AUTOSAR XML (schema 3.1.2)
package /Components/SWC_CoEmSTT
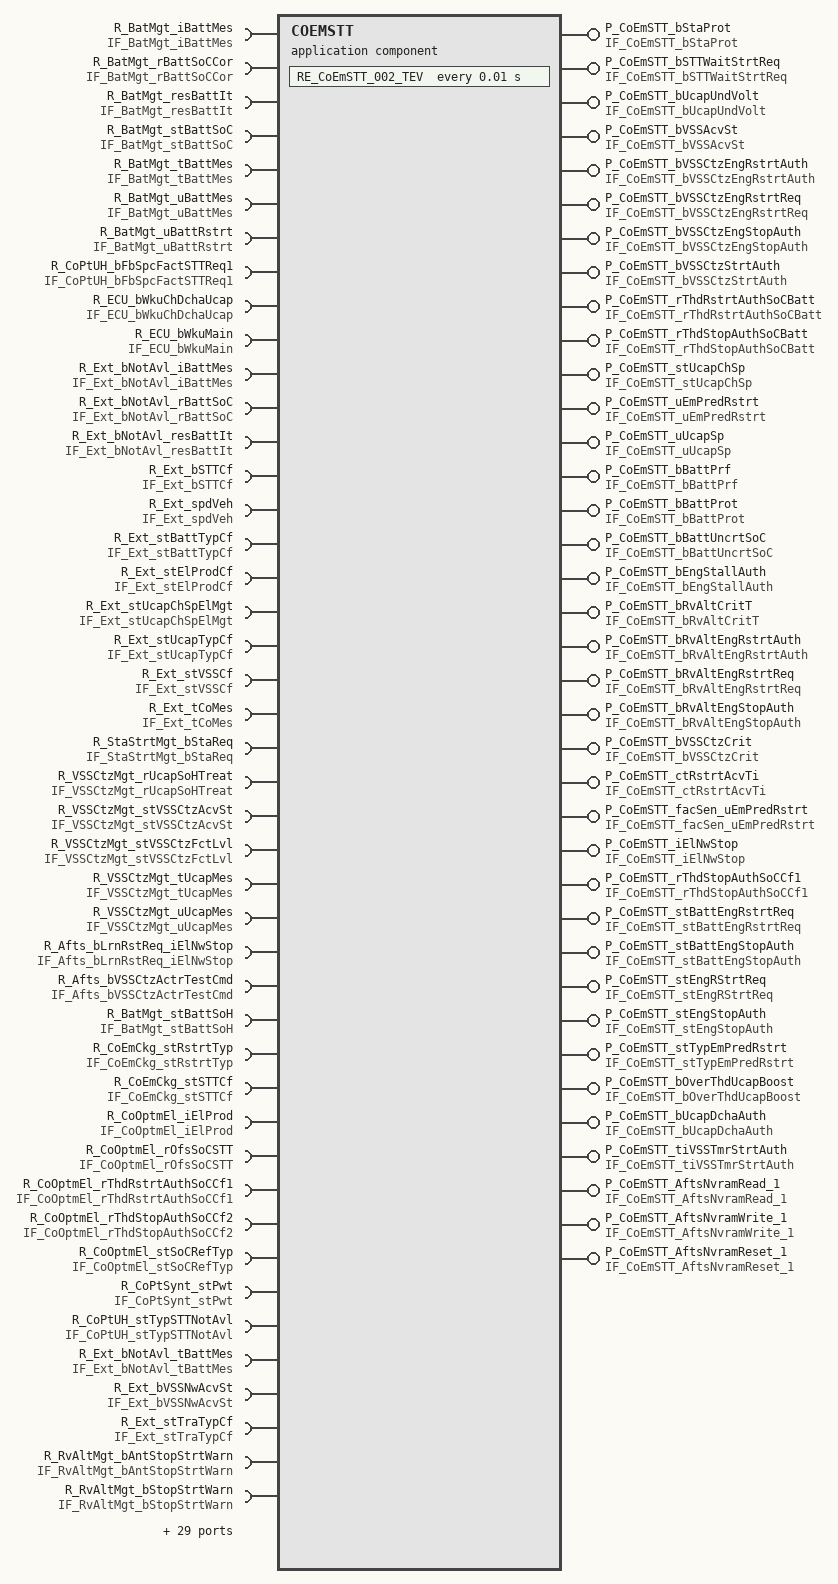
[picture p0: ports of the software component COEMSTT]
  application software component type COEMSTT
    71 x require port:
      R_BatMgt_iBattMes: unqueued-receiver-com-spec{data-element=BatMgt_iBattMes, init-value=BatMgt_iBattMes_in, resync-time=0}, required-interface=IF_BatMgt_iBattMes
      R_BatMgt_rBattSoCCor: unqueued-receiver-com-spec{data-element=BatMgt_rBattSoCCor, init-value=BatMgt_rBattSoCCor_in, resync-time=0}, required-interface=IF_BatMgt_rBattSoCCor
      R_BatMgt_resBattIt: unqueued-receiver-com-spec{data-element=BatMgt_resBattIt, init-value=BatMgt_resBattIt_in, resync-time=0}, required-interface=IF_BatMgt_resBattIt
      R_BatMgt_stBattSoC: unqueued-receiver-com-spec{data-element=BatMgt_stBattSoC, init-value=BatMgt_stBattSoC_in, resync-time=0}, required-interface=IF_BatMgt_stBattSoC
      R_BatMgt_tBattMes: unqueued-receiver-com-spec{data-element=BatMgt_tBattMes, init-value=BatMgt_tBattMes_in, resync-time=0}, required-interface=IF_BatMgt_tBattMes
      R_BatMgt_uBattMes: unqueued-receiver-com-spec{data-element=BatMgt_uBattMes, init-value=BatMgt_uBattMes_in, resync-time=0}, required-interface=IF_BatMgt_uBattMes
      R_BatMgt_uBattRstrt: unqueued-receiver-com-spec{data-element=BatMgt_uBattRstrt, init-value=BatMgt_uBattRstrt_in, resync-time=0}, required-interface=IF_BatMgt_uBattRstrt
      R_CoPtUH_bFbSpcFactSTTReq1: unqueued-receiver-com-spec{data-element=CoPtUH_bFbSpcFactSTTReq1, init-value=ConstantValue, resync-time=0}, required-interface=IF_CoPtUH_bFbSpcFactSTTReq1
      R_ECU_bWkuChDchaUcap: unqueued-receiver-com-spec{data-element=ECU_bWkuChDchaUcap, init-value=ECU_bWkuChDchaUcap_in, resync-time=0}, required-interface=IF_ECU_bWkuChDchaUcap
      R_ECU_bWkuMain: unqueued-receiver-com-spec{data-element=ECU_bWkuMain, init-value=ECU_bWkuMain_in, resync-time=0}, required-interface=IF_ECU_bWkuMain
      R_Ext_bNotAvl_iBattMes: unqueued-receiver-com-spec{data-element=Ext_bNotAvl_iBattMes, init-value=Ext_bNotAvl_iBattMes_in, resync-time=0}, required-interface=IF_Ext_bNotAvl_iBattMes
      R_Ext_bNotAvl_rBattSoC: unqueued-receiver-com-spec{data-element=Ext_bNotAvl_rBattSoC, init-value=Ext_bNotAvl_rBattSoC_in, resync-time=0}, required-interface=IF_Ext_bNotAvl_rBattSoC
      R_Ext_bNotAvl_resBattIt: unqueued-receiver-com-spec{data-element=Ext_bNotAvl_resBattIt, init-value=Ext_bNotAvl_resBattIt_in, resync-time=0}, required-interface=IF_Ext_bNotAvl_resBattIt
      R_Ext_bSTTCf: unqueued-receiver-com-spec{data-element=Ext_bSTTCf, init-value=Ext_bSTTCf_in, resync-time=0}, required-interface=IF_Ext_bSTTCf
      R_Ext_spdVeh: unqueued-receiver-com-spec{data-element=Ext_spdVeh, init-value=Ext_spdVeh_in, resync-time=0}, required-interface=IF_Ext_spdVeh
      R_Ext_stBattTypCf: unqueued-receiver-com-spec{data-element=Ext_stBattTypCf, init-value=Ext_stBattTypCf_in, resync-time=0}, required-interface=IF_Ext_stBattTypCf
      R_Ext_stElProdCf: unqueued-receiver-com-spec{data-element=Ext_stElProdCf, init-value=Ext_stElProdCf_in, resync-time=0}, required-interface=IF_Ext_stElProdCf
      R_Ext_stUcapChSpElMgt: unqueued-receiver-com-spec{data-element=Ext_stUcapChSpElMgt, init-value=Ext_stUcapChSpElMgt_in, resync-time=0}, required-interface=IF_Ext_stUcapChSpElMgt
      R_Ext_stUcapTypCf: unqueued-receiver-com-spec{data-element=Ext_stUcapTypCf, init-value=Ext_stUcapTypCf_in, resync-time=0}, required-interface=IF_Ext_stUcapTypCf
      R_Ext_stVSSCf: unqueued-receiver-com-spec{data-element=Ext_stVSSCf, init-value=Ext_stVSSCf_in, resync-time=0}, required-interface=IF_Ext_stVSSCf
      R_Ext_tCoMes: unqueued-receiver-com-spec{data-element=Ext_tCoMes, init-value=ConstantValue1, resync-time=0}, required-interface=IF_Ext_tCoMes
      R_StaStrtMgt_bStaReq: unqueued-receiver-com-spec{data-element=StaStrtMgt_bStaReq, init-value=StaStrtMgt_bStaReq_in, resync-time=0}, required-interface=IF_StaStrtMgt_bStaReq
      R_VSSCtzMgt_rUcapSoHTreat: unqueued-receiver-com-spec{data-element=VSSCtzMgt_rUcapSoHTreat, init-value=VSSCtzMgt_rUcapSoHTreat_in, resync-time=0}, required-interface=IF_VSSCtzMgt_rUcapSoHTreat
      R_VSSCtzMgt_stVSSCtzAcvSt: unqueued-receiver-com-spec{data-element=VSSCtzMgt_stVSSCtzAcvSt, init-value=VSSCtzMgt_stVSSCtzAcvSt_in, resync-time=0}, required-interface=IF_VSSCtzMgt_stVSSCtzAcvSt
      R_VSSCtzMgt_stVSSCtzFctLvl: unqueued-receiver-com-spec{data-element=VSSCtzMgt_stVSSCtzFctLvl, init-value=VSSCtzMgt_stVSSCtzFctLvl_in, resync-time=0}, required-interface=IF_VSSCtzMgt_stVSSCtzFctLvl
      R_VSSCtzMgt_tUcapMes: unqueued-receiver-com-spec{data-element=VSSCtzMgt_tUcapMes, init-value=VSSCtzMgt_tUcapMes_in, resync-time=0}, required-interface=IF_VSSCtzMgt_tUcapMes
      R_VSSCtzMgt_uUcapMes: unqueued-receiver-com-spec{data-element=VSSCtzMgt_uUcapMes, init-value=VSSCtzMgt_uUcapMes_in, resync-time=0}, required-interface=IF_VSSCtzMgt_uUcapMes
      R_Afts_bLrnRstReq_iElNwStop: unqueued-receiver-com-spec{data-element=Afts_bLrnRstReq_iElNwStop, init-value=Afts_bLrnRstReq_iElNwStop_in, resync-time=0}, required-interface=IF_Afts_bLrnRstReq_iElNwStop
      R_Afts_bVSSCtzActrTestCmd: unqueued-receiver-com-spec{data-element=Afts_bVSSCtzActrTestCmd, init-value=Afts_bVSSCtzActrTestCmd_in, resync-time=0}, required-interface=IF_Afts_bVSSCtzActrTestCmd
      R_BatMgt_stBattSoH: unqueued-receiver-com-spec{data-element=BatMgt_stBattSoH, init-value=BatMgt_stBattSoH_in, resync-time=0}, required-interface=IF_BatMgt_stBattSoH
      R_CoEmCkg_stRstrtTyp: unqueued-receiver-com-spec{data-element=CoEmCkg_stRstrtTyp, init-value=CoEmCkg_stRstrtTyp_in, resync-time=0}, required-interface=IF_CoEmCkg_stRstrtTyp
      R_CoEmCkg_stSTTCf: unqueued-receiver-com-spec{data-element=CoEmCkg_stSTTCf, init-value=CoEmCkg_stSTTCf_in, resync-time=0}, required-interface=IF_CoEmCkg_stSTTCf
      R_CoOptmEl_iElProd: unqueued-receiver-com-spec{data-element=CoOptmEl_iElProd, init-value=CoOptmEl_iElProd_in, resync-time=0}, required-interface=IF_CoOptmEl_iElProd
      R_CoOptmEl_rOfsSoCSTT: unqueued-receiver-com-spec{data-element=CoOptmEl_rOfsSoCSTT, init-value=CoOptmEl_rOfsSoCSTT_in, resync-time=0}, required-interface=IF_CoOptmEl_rOfsSoCSTT
      R_CoOptmEl_rThdRstrtAuthSoCCf1: unqueued-receiver-com-spec{data-element=CoOptmEl_rThdRstrtAuthSoCCf1, init-value=CoOptmEl_rThdRstrtAuthSoCCf1_in, resync-time=0}, required-interface=IF_CoOptmEl_rThdRstrtAuthSoCCf1
      R_CoOptmEl_rThdStopAuthSoCCf2: unqueued-receiver-com-spec{data-element=CoOptmEl_rThdStopAuthSoCCf2, init-value=CoOptmEl_rThdStopAuthSoCCf2_in, resync-time=0}, required-interface=IF_CoOptmEl_rThdStopAuthSoCCf2
      R_CoOptmEl_stSoCRefTyp: unqueued-receiver-com-spec{data-element=CoOptmEl_stSoCRefTyp, init-value=CoOptmEl_stSoCRefTyp_in, resync-time=0}, required-interface=IF_CoOptmEl_stSoCRefTyp
      R_CoPtSynt_stPwt: unqueued-receiver-com-spec{data-element=CoPtSynt_stPwt, init-value=CoPtSynt_stPwt_in, resync-time=0}, required-interface=IF_CoPtSynt_stPwt
      R_CoPtUH_stTypSTTNotAvl: unqueued-receiver-com-spec{data-element=CoPtUH_stTypSTTNotAvl, init-value=CoPtUH_stTypSTTNotAvl_in, resync-time=0}, required-interface=IF_CoPtUH_stTypSTTNotAvl
      R_Ext_bNotAvl_tBattMes: unqueued-receiver-com-spec{data-element=Ext_bNotAvl_tBattMes, init-value=Ext_bNotAvl_tBattMes_in, resync-time=0}, required-interface=IF_Ext_bNotAvl_tBattMes
      R_Ext_bVSSNwAcvSt: unqueued-receiver-com-spec{data-element=Ext_bVSSNwAcvSt, init-value=Ext_bVSSNwAcvSt_in, resync-time=0}, required-interface=IF_Ext_bVSSNwAcvSt
      R_Ext_stTraTypCf: unqueued-receiver-com-spec{data-element=Ext_stTraTypCf, init-value=Ext_stTraTypCf_in, resync-time=0}, required-interface=IF_Ext_stTraTypCf
      R_RvAltMgt_bAntStopStrtWarn: unqueued-receiver-com-spec{data-element=RvAltMgt_bAntStopStrtWarn, init-value=RvAltMgt_bAntStopStrtWarn_in, resync-time=0}, required-interface=IF_RvAltMgt_bAntStopStrtWarn
      R_RvAltMgt_bStopStrtWarn: unqueued-receiver-com-spec{data-element=RvAltMgt_bStopStrtWarn, init-value=RvAltMgt_bStopStrtWarn_in, resync-time=0}, required-interface=IF_RvAltMgt_bStopStrtWarn
      R_RvAltMgt_stRvAltRstrtFbCmd: unqueued-receiver-com-spec{data-element=RvAltMgt_stRvAltRstrtFbCmd, init-value=RvAltMgt_stRvAltRstrtFbCmd_in, resync-time=0}, required-interface=IF_RvAltMgt_stRvAltRstrtFbCmd
      R_RvAltMgt_tRvAltStatEstim: unqueued-receiver-com-spec{data-element=RvAltMgt_tRvAltStatEstim, init-value=RvAltMgt_tRvAltStatEstim_in, resync-time=0}, required-interface=IF_RvAltMgt_tRvAltStatEstim
      R_StaRstrtMgt_bProt10StopInh: unqueued-receiver-com-spec{data-element=StaRstrtMgt_bProt10StopInh, init-value=StaRstrtMgt_bProt10StopInh_in, resync-time=0}, required-interface=IF_StaRstrtMgt_bProt10StopInh
      R_StaRstrtMgt_stStaRstrtFbCmd: unqueued-receiver-com-spec{data-element=StaRstrtMgt_stStaRstrtFbCmd, init-value=StaRstrtMgt_stStaRstrtFbCmd_in, resync-time=0}, required-interface=IF_StaRstrtMgt_stStaRstrtFbCmd
      R_StopStrtEng_stCdnNxtCkg: unqueued-receiver-com-spec{data-element=StopStrtEng_stCdnNxtCkg, init-value=StopStrtEng_stCdnNxtCkg_in, resync-time=0}, required-interface=IF_StopStrtEng_stCdnNxtCkg
      R_VSSCtzMgt_bUcapSerAcvTest: unqueued-receiver-com-spec{data-element=VSSCtzMgt_bUcapSerAcvTest, init-value=VSSCtzMgt_bUcapSerAcvTest_in, resync-time=0}, required-interface=IF_VSSCtzMgt_bUcapSerAcvTest
      R_VSSCtzMgt_resVSSCtzEstim: unqueued-receiver-com-spec{data-element=VSSCtzMgt_resVSSCtzEstim, init-value=VSSCtzMgt_resVSSCtzEstim_in, resync-time=0}, required-interface=IF_VSSCtzMgt_resVSSCtzEstim
      R_VSSCtzMgt_stUcapDchaRslt: unqueued-receiver-com-spec{data-element=VSSCtzMgt_stUcapDchaRslt, init-value=VSSCtzMgt_stUcapDchaRslt_in, resync-time=0}, required-interface=IF_VSSCtzMgt_stUcapDchaRslt
      R_Afts_bLrnRstReq_uEmPredRstrt: unqueued-receiver-com-spec{data-element=Afts_bLrnRstReq_uEmPredRstrt, init-value=Afts_bLrnRstReq_uEmPredRstrt_in, resync-time=0}, required-interface=IF_Afts_bLrnRstReq_uEmPredRstrt
      R_Afts_bUcapChgIdc: unqueued-receiver-com-spec{data-element=Afts_bUcapChgIdc, init-value=Afts_bUcapChgIdc_in, resync-time=0}, required-interface=IF_Afts_bUcapChgIdc
      R_BatMgt_iBattMaxCkg: unqueued-receiver-com-spec{data-element=BatMgt_iBattMaxCkg, init-value=BatMgt_iBattMaxCkg_in, resync-time=0}, required-interface=IF_BatMgt_iBattMaxCkg
      R_BatMgt_uBattMinCkg: unqueued-receiver-com-spec{data-element=BatMgt_uBattMinCkg, init-value=BatMgt_uBattMinCkg_in, resync-time=0}, required-interface=IF_BatMgt_uBattMinCkg
      R_CoPtUH_bRStrtReqAvl: unqueued-receiver-com-spec{data-element=CoPtUH_bRStrtReqAvl, init-value=CoPtUH_bRStrtReqAvl_in, resync-time=0}, required-interface=IF_CoPtUH_bRStrtReqAvl
      R_Ext_rAltCycOp: unqueued-receiver-com-spec{data-element=Ext_rAltCycOp, init-value=Ext_rAltCycOp_in, resync-time=0}, required-interface=IF_Ext_rAltCycOp
      R_StaStrtMgt_bDmgLimStopInh: unqueued-receiver-com-spec{data-element=StaStrtMgt_bDmgLimStopInh, init-value=StaStrtMgt_bDmgLimStopInh_in, resync-time=0}, required-interface=IF_StaStrtMgt_bDmgLimStopInh
      R_FRM_bAcvCoEmSTTVSSCtzStrt: required-interface=FunctionInhibition
      R_FRM_bInhCoEmSTT_uEmPredRstrt: required-interface=FunctionInhibition
      R_FRM_bInhCoEmSTTNwCurClcStop: required-interface=FunctionInhibition
      R_FRM_bInhCoEmSTTStopAuth: required-interface=FunctionInhibition
      R_FRM_bInhCoEmSTTVSSCtzStrt: required-interface=FunctionInhibition
      R_FRM_bInhCoEmSTTWaitStrt: required-interface=FunctionInhibition
      R_FRM_bAcvCoEmSTTDftUcapCurSp: required-interface=FunctionInhibition
      R_FRM_bAcvCoEmSTTDftUcapVoltSp: required-interface=FunctionInhibition
      R_FRM_bAcvCoEmSTTRstrtReq: required-interface=FunctionInhibition
      R_FRM_bInhCoEmSTT_uVSSCtzRstrt: required-interface=FunctionInhibition
      R_FRM_bInhCoEmSTTNwCurMv: required-interface=FunctionInhibition
      R_FRM_bAcvCoEmSTTCutReq: required-interface=FunctionInhibition
    34 x provide port:
      P_CoEmSTT_bStaProt: unqueued-sender-com-spec{data-element=CoEmSTT_bStaProt, can-invalidate=false, init-value=CoEmSTT_bStaProt_out}, provided-interface=IF_CoEmSTT_bStaProt
      P_CoEmSTT_bSTTWaitStrtReq: unqueued-sender-com-spec{data-element=CoEmSTT_bSTTWaitStrtReq, can-invalidate=false, init-value=CoEmSTT_bSTTWaitStrtReq_out}, provided-interface=IF_CoEmSTT_bSTTWaitStrtReq
      P_CoEmSTT_bUcapUndVolt: unqueued-sender-com-spec{data-element=CoEmSTT_bUcapUndVolt, can-invalidate=false, init-value=CoEmSTT_bUcapUndVolt_out}, provided-interface=IF_CoEmSTT_bUcapUndVolt
      P_CoEmSTT_bVSSAcvSt: unqueued-sender-com-spec{data-element=CoEmSTT_bVSSAcvSt, can-invalidate=false, init-value=CoEmSTT_bVSSAcvSt_out}, provided-interface=IF_CoEmSTT_bVSSAcvSt
      P_CoEmSTT_bVSSCtzEngRstrtAuth: unqueued-sender-com-spec{data-element=CoEmSTT_bVSSCtzEngRstrtAuth, can-invalidate=false, init-value=CoEmSTT_bVSSCtzEngRstrtAuth_out}, provided-interface=IF_CoEmSTT_bVSSCtzEngRstrtAuth
      P_CoEmSTT_bVSSCtzEngRstrtReq: unqueued-sender-com-spec{data-element=CoEmSTT_bVSSCtzEngRstrtReq, can-invalidate=false, init-value=CoEmSTT_bVSSCtzEngRstrtReq_out}, provided-interface=IF_CoEmSTT_bVSSCtzEngRstrtReq
      P_CoEmSTT_bVSSCtzEngStopAuth: unqueued-sender-com-spec{data-element=CoEmSTT_bVSSCtzEngStopAuth, can-invalidate=false, init-value=CoEmSTT_bVSSCtzEngStopAuth_out}, provided-interface=IF_CoEmSTT_bVSSCtzEngStopAuth
      P_CoEmSTT_bVSSCtzStrtAuth: unqueued-sender-com-spec{data-element=CoEmSTT_bVSSCtzStrtAuth, can-invalidate=false, init-value=CoEmSTT_bVSSCtzStrtAuth_out}, provided-interface=IF_CoEmSTT_bVSSCtzStrtAuth
      P_CoEmSTT_rThdRstrtAuthSoCBatt: unqueued-sender-com-spec{data-element=CoEmSTT_rThdRstrtAuthSoCBatt, can-invalidate=false, init-value=CoEmSTT_rThdRstrtAuthSoCBatt_out}, provided-interface=IF_CoEmSTT_rThdRstrtAuthSoCBatt
      P_CoEmSTT_rThdStopAuthSoCBatt: unqueued-sender-com-spec{data-element=CoEmSTT_rThdStopAuthSoCBatt, can-invalidate=false, init-value=CoEmSTT_rThdStopAuthSoCBatt_out}, provided-interface=IF_CoEmSTT_rThdStopAuthSoCBatt
      P_CoEmSTT_stUcapChSp: unqueued-sender-com-spec{data-element=CoEmSTT_stUcapChSp, can-invalidate=false, init-value=CoEmSTT_stUcapChSp_out}, provided-interface=IF_CoEmSTT_stUcapChSp
      P_CoEmSTT_uEmPredRstrt: unqueued-sender-com-spec{data-element=CoEmSTT_uEmPredRstrt, can-invalidate=false, init-value=CoEmSTT_uEmPredRstrt_out}, provided-interface=IF_CoEmSTT_uEmPredRstrt
      P_CoEmSTT_uUcapSp: unqueued-sender-com-spec{data-element=CoEmSTT_uUcapSp, can-invalidate=false, init-value=CoEmSTT_uUcapSp_out}, provided-interface=IF_CoEmSTT_uUcapSp
      P_CoEmSTT_bBattPrf: unqueued-sender-com-spec{data-element=CoEmSTT_bBattPrf, can-invalidate=false, init-value=CoEmSTT_bBattPrf_out}, provided-interface=IF_CoEmSTT_bBattPrf
      P_CoEmSTT_bBattProt: unqueued-sender-com-spec{data-element=CoEmSTT_bBattProt, can-invalidate=false, init-value=CoEmSTT_bBattProt_out}, provided-interface=IF_CoEmSTT_bBattProt
      P_CoEmSTT_bBattUncrtSoC: unqueued-sender-com-spec{data-element=CoEmSTT_bBattUncrtSoC, can-invalidate=false, init-value=CoEmSTT_bBattUncrtSoC_out}, provided-interface=IF_CoEmSTT_bBattUncrtSoC
      P_CoEmSTT_bEngStallAuth: unqueued-sender-com-spec{data-element=CoEmSTT_bEngStallAuth, can-invalidate=false, init-value=ConstantValue3}, provided-interface=IF_CoEmSTT_bEngStallAuth
      P_CoEmSTT_bRvAltCritT: unqueued-sender-com-spec{data-element=CoEmSTT_bRvAltCritT, can-invalidate=false, init-value=CoEmSTT_bRvAltCritT_out}, provided-interface=IF_CoEmSTT_bRvAltCritT
      P_CoEmSTT_bRvAltEngRstrtAuth: unqueued-sender-com-spec{data-element=CoEmSTT_bRvAltEngRstrtAuth, can-invalidate=false, init-value=CoEmSTT_bRvAltEngRstrtAuth_out}, provided-interface=IF_CoEmSTT_bRvAltEngRstrtAuth
      P_CoEmSTT_bRvAltEngRstrtReq: unqueued-sender-com-spec{data-element=CoEmSTT_bRvAltEngRstrtReq, can-invalidate=false, init-value=CoEmSTT_bRvAltEngRstrtReq_out}, provided-interface=IF_CoEmSTT_bRvAltEngRstrtReq
      P_CoEmSTT_bRvAltEngStopAuth: unqueued-sender-com-spec{data-element=CoEmSTT_bRvAltEngStopAuth, can-invalidate=false, init-value=CoEmSTT_bRvAltEngStopAuth_out}, provided-interface=IF_CoEmSTT_bRvAltEngStopAuth
      P_CoEmSTT_bVSSCtzCrit: unqueued-sender-com-spec{data-element=CoEmSTT_bVSSCtzCrit, can-invalidate=false, init-value=CoEmSTT_bVSSCtzCrit_out}, provided-interface=IF_CoEmSTT_bVSSCtzCrit
      P_CoEmSTT_ctRstrtAcvTi: unqueued-sender-com-spec{data-element=CoEmSTT_ctRstrtAcvTi, can-invalidate=false, init-value=CoEmSTT_ctRstrtAcvTi_out}, provided-interface=IF_CoEmSTT_ctRstrtAcvTi
      P_CoEmSTT_facSen_uEmPredRstrt: unqueued-sender-com-spec{data-element=CoEmSTT_facSen_uEmPredRstrt, can-invalidate=false, init-value=CoEmSTT_facSen_uEmPredRstrt_out}, provided-interface=IF_CoEmSTT_facSen_uEmPredRstrt
      P_CoEmSTT_iElNwStop: unqueued-sender-com-spec{data-element=CoEmSTT_iElNwStop, can-invalidate=false, init-value=CoEmSTT_iElNwStop_out}, provided-interface=IF_CoEmSTT_iElNwStop
      P_CoEmSTT_rThdStopAuthSoCCf1: unqueued-sender-com-spec{data-element=CoEmSTT_rThdStopAuthSoCCf1, can-invalidate=false, init-value=CoEmSTT_rThdStopAuthSoCCf1_out}, provided-interface=IF_CoEmSTT_rThdStopAuthSoCCf1
      P_CoEmSTT_stBattEngRstrtReq: unqueued-sender-com-spec{data-element=CoEmSTT_stBattEngRstrtReq, can-invalidate=false, init-value=CoEmSTT_stBattEngRstrtReq_out}, provided-interface=IF_CoEmSTT_stBattEngRstrtReq
      P_CoEmSTT_stBattEngStopAuth: unqueued-sender-com-spec{data-element=CoEmSTT_stBattEngStopAuth, can-invalidate=false, init-value=CoEmSTT_stBattEngStopAuth_out}, provided-interface=IF_CoEmSTT_stBattEngStopAuth
      P_CoEmSTT_stEngRStrtReq: unqueued-sender-com-spec{data-element=CoEmSTT_stEngRStrtReq, can-invalidate=false, init-value=ConstantValue5}, provided-interface=IF_CoEmSTT_stEngRStrtReq
      P_CoEmSTT_stEngStopAuth: unqueued-sender-com-spec{data-element=CoEmSTT_stEngStopAuth, can-invalidate=false, init-value=CoEmSTT_stEngStopAuth_out}, provided-interface=IF_CoEmSTT_stEngStopAuth
      P_CoEmSTT_stTypEmPredRstrt: unqueued-sender-com-spec{data-element=CoEmSTT_stTypEmPredRstrt, can-invalidate=false, init-value=CoEmSTT_stTypEmPredRstrt_out}, provided-interface=IF_CoEmSTT_stTypEmPredRstrt
      P_CoEmSTT_bOverThdUcapBoost: unqueued-sender-com-spec{data-element=CoEmSTT_bOverThdUcapBoost, can-invalidate=false, init-value=CoEmSTT_bOverThdUcapBoost_out}, provided-interface=IF_CoEmSTT_bOverThdUcapBoost
      P_CoEmSTT_bUcapDchaAuth: unqueued-sender-com-spec{data-element=CoEmSTT_bUcapDchaAuth, can-invalidate=false, init-value=CoEmSTT_bUcapDchaAuth_out}, provided-interface=IF_CoEmSTT_bUcapDchaAuth
      P_CoEmSTT_tiVSSTmrStrtAuth: unqueued-sender-com-spec{data-element=CoEmSTT_tiVSSTmrStrtAuth, can-invalidate=false, init-value=CoEmSTT_tiVSSTmrStrtAuth_out}, provided-interface=IF_CoEmSTT_tiVSSTmrStrtAuth
    require port R_UCE_stWkuMainRelSt: required-interface=IF_UCE_stWkuMainRelSt
    require port R_EcuM_CurrentMode: required-interface=EcuM_CurrentMode
    provide port P_CoEmSTT_AftsNvramRead_1: server-com-spec{operation=op_CoEmSTT_AftsNvramRead_1, queue-length=1}, provided-interface=IF_CoEmSTT_AftsNvramRead_1
    provide port P_CoEmSTT_AftsNvramWrite_1: server-com-spec{operation=op_CoEmSTT_AftsNvramWrite_1, queue-length=1}, provided-interface=IF_CoEmSTT_AftsNvramWrite_1
    provide port P_CoEmSTT_AftsNvramReset_1: server-com-spec{operation=op_CoEmSTT_AftsNvramReset_1, queue-length=1}, provided-interface=IF_CoEmSTT_AftsNvramReset_1
  93 x constant specification:
    Afts_bLrnRstReq_iElNwStop_in
      value:
        boolean literal Afts_bLrnRstReq_iElNwStop_in: type=DT_Afts_bLrnRstReq_iElNwStop, value=false
    Afts_bLrnRstReq_uEmPredRstrt_in
      value:
        boolean literal Afts_bLrnRstReq_uEmPredRstrt_in: type=DT_Afts_bLrnRstReq_uEmPredRstrt, value=false
    Afts_bUcapChgIdc_in
      value:
        boolean literal Afts_bUcapChgIdc_in: type=DT_Afts_bUcapChgIdc, value=false
    Afts_bVSSCtzActrTestCmd_in
      value:
        boolean literal Afts_bVSSCtzActrTestCmd_in: type=DT_Afts_bVSSCtzActrTestCmd, value=false
    BatMgt_iBattMaxCkg_in
      value:
        integer literal BatMgt_iBattMaxCkg_in: type=DT_BatMgt_iBattMaxCkg, value=-18
    BatMgt_iBattMes_in
      value:
        integer literal BatMgt_iBattMes_in: type=DT_BatMgt_iBattMes, value=0
    BatMgt_rBattSoCCor_in
      value:
        integer literal BatMgt_rBattSoCCor_in: type=DT_BatMgt_rBattSoCCor, value=0
    BatMgt_resBattIt_in
      value:
        integer literal BatMgt_resBattIt_in: type=DT_BatMgt_resBattIt, value=0
    BatMgt_stBattSoC_in
      value:
        integer literal BatMgt_stBattSoC_in: type=DT_BatMgt_stBattSoC, value=0
    BatMgt_stBattSoH_in
      value:
        integer literal BatMgt_stBattSoH_in: type=DT_BatMgt_stBattSoH, value=0
    BatMgt_tBattMes_in
      value:
        integer literal BatMgt_tBattMes_in: type=DT_BatMgt_tBattMes, value=0
    BatMgt_uBattMes_in
      value:
        integer literal BatMgt_uBattMes_in: type=DT_BatMgt_uBattMes, value=640
    BatMgt_uBattMinCkg_in
      value:
        integer literal BatMgt_uBattMinCkg_in: type=DT_BatMgt_uBattMinCkg, value=384
    BatMgt_uBattRstrt_in
      value:
        integer literal BatMgt_uBattRstrt_in: type=DT_BatMgt_uBattRstrt, value=0
    CoEmCkg_stRstrtTyp_in
      value:
        integer literal CoEmCkg_stRstrtTyp_in: type=DT_CoEmCkg_stRstrtTyp, value=0
    CoEmCkg_stSTTCf_in
      value:
        integer literal CoEmCkg_stSTTCf_in: type=DT_CoEmCkg_stSTTCf, value=0
    CoEmSTT_bBattPrf_out
      value:
        boolean literal CoEmSTT_bBattPrf_out: type=DT_CoEmSTT_bBattPrf, value=false
    CoEmSTT_bBattProt_out
      value:
        boolean literal CoEmSTT_bBattProt_out: type=DT_CoEmSTT_bBattProt, value=false
    CoEmSTT_bBattUncrtSoC_out
      value:
        boolean literal CoEmSTT_bBattUncrtSoC_out: type=DT_CoEmSTT_bBattUncrtSoC, value=false
    CoEmSTT_bOverThdUcapBoost_out
      value:
        boolean literal CoEmSTT_bOverThdUcapBoost_out: type=DT_CoEmSTT_bOverThdUcapBoost, value=false
    CoEmSTT_bRvAltCritT_out
      value:
        boolean literal CoEmSTT_bRvAltCritT_out: type=DT_CoEmSTT_bRvAltCritT, value=false
    CoEmSTT_bRvAltEngRstrtAuth_out
      value:
        boolean literal CoEmSTT_bRvAltEngRstrtAuth_out: type=DT_CoEmSTT_bRvAltEngRstrtAuth, value=true
    CoEmSTT_bRvAltEngRstrtReq_out
      value:
        boolean literal CoEmSTT_bRvAltEngRstrtReq_out: type=DT_CoEmSTT_bRvAltEngRstrtReq, value=false
    CoEmSTT_bRvAltEngStopAuth_out
      value:
        boolean literal CoEmSTT_bRvAltEngStopAuth_out: type=DT_CoEmSTT_bRvAltEngStopAuth, value=true
    CoEmSTT_bStaProt_out
      value:
        boolean literal CoEmSTT_bStaProt_out: type=DT_CoEmSTT_bStaProt, value=false
    CoEmSTT_bSTTWaitStrtReq_out
      value:
        boolean literal CoEmSTT_bSTTWaitStrtReq_out: type=DT_CoEmSTT_bSTTWaitStrtReq, value=false
    CoEmSTT_bUcapDchaAuth_out
      value:
        boolean literal CoEmSTT_bUcapDchaAuth_out: type=DT_CoEmSTT_bUcapDchaAuth, value=true
    CoEmSTT_bUcapUndVolt_out
      value:
        boolean literal CoEmSTT_bUcapUndVolt_out: type=DT_CoEmSTT_bUcapUndVolt, value=false
    CoEmSTT_bVSSAcvSt_out
      value:
        boolean literal CoEmSTT_bVSSAcvSt_out: type=DT_CoEmSTT_bVSSAcvSt, value=false
    CoEmSTT_bVSSCtzCrit_out
      value:
        boolean literal CoEmSTT_bVSSCtzCrit_out: type=DT_CoEmSTT_bVSSCtzCrit, value=false
    CoEmSTT_bVSSCtzEngRstrtAuth_out
      value:
        boolean literal CoEmSTT_bVSSCtzEngRstrtAuth_out: type=DT_CoEmSTT_bVSSCtzEngRstrtAuth, value=true
    CoEmSTT_bVSSCtzEngRstrtReq_out
      value:
        boolean literal CoEmSTT_bVSSCtzEngRstrtReq_out: type=DT_CoEmSTT_bVSSCtzEngRstrtReq, value=false
    CoEmSTT_bVSSCtzEngStopAuth_out
      value:
        boolean literal CoEmSTT_bVSSCtzEngStopAuth_out: type=DT_CoEmSTT_bVSSCtzEngStopAuth, value=true
    CoEmSTT_bVSSCtzStrtAuth_out
      value:
        boolean literal CoEmSTT_bVSSCtzStrtAuth_out: type=DT_CoEmSTT_bVSSCtzStrtAuth, value=false
    CoEmSTT_ctRstrtAcvTi_out
      value:
        integer literal CoEmSTT_ctRstrtAcvTi_out: type=DT_CoEmSTT_ctRstrtAcvTi, value=0
    CoEmSTT_facSen_uEmPredRstrt_out
      value:
        integer literal CoEmSTT_facSen_uEmPredRstrt_out: type=DT_CoEmSTT_facSen_uEmPredRstrt, value=0
    CoEmSTT_iElNwStop_out
      value:
        integer literal CoEmSTT_iElNwStop_out: type=DT_CoEmSTT_iElNwStop, value=40
    CoEmSTT_rThdRstrtAuthSoCBatt_out
      value:
        integer literal CoEmSTT_rThdRstrtAuthSoCBatt_out: type=DT_CoEmSTT_rThdRstrtAuthSoCBatt, value=1120
    CoEmSTT_rThdStopAuthSoCBatt_out
      value:
        integer literal CoEmSTT_rThdStopAuthSoCBatt_out: type=DT_CoEmSTT_rThdStopAuthSoCBatt, value=1120
    CoEmSTT_rThdStopAuthSoCCf1_out
      value:
        integer literal CoEmSTT_rThdStopAuthSoCCf1_out: type=DT_CoEmSTT_rThdStopAuthSoCCf1, value=1120
    CoEmSTT_stBattEngRstrtReq_out
      value:
        integer literal CoEmSTT_stBattEngRstrtReq_out: type=DT_CoEmSTT_stBattEngRstrtReq, value=0
    CoEmSTT_stBattEngStopAuth_out
      value:
        integer literal CoEmSTT_stBattEngStopAuth_out: type=DT_CoEmSTT_stBattEngStopAuth, value=1
    CoEmSTT_stEngStopAuth_out
      value:
        integer literal CoEmSTT_stEngStopAuth_out: type=DT_CoEmSTT_stEngStopAuth, value=1
    CoEmSTT_stTypEmPredRstrt_out
      value:
        integer literal CoEmSTT_stTypEmPredRstrt_out: type=DT_CoEmSTT_stTypEmPredRstrt, value=0
    CoEmSTT_stUcapChSp_out
      value:
        integer literal CoEmSTT_stUcapChSp_out: type=DT_CoEmSTT_stUcapChSp, value=0
    CoEmSTT_tiVSSTmrStrtAuth_out
      value:
        integer literal CoEmSTT_tiVSSTmrStrtAuth_out: type=DT_CoEmSTT_tiVSSTmrStrtAuth, value=0
    CoEmSTT_uEmPredRstrt_out
      value:
        integer literal CoEmSTT_uEmPredRstrt_out: type=DT_CoEmSTT_uEmPredRstrt, value=80
    CoEmSTT_uUcapSp_out
      value:
        integer literal CoEmSTT_uUcapSp_out: type=DT_CoEmSTT_uUcapSp, value=0
    ConstantValue
      value:
        boolean literal ConstantValue: type=DT_CoPtUH_bFbSpcFactSTTReq1, value=false
    ConstantValue1
      value:
        integer literal ConstantValue1: type=DT_Ext_tCoMes, value=20
    ConstantValue3
      value:
        boolean literal ConstantValue3: type=DT_CoEmSTT_bEngStallAuth, value=false
    ConstantValue5
      value:
        integer literal ConstantValue5: type=DT_CoEmSTT_stEngRStrtReq, value=0
    CoOptmEl_iElProd_in
      value:
        integer literal CoOptmEl_iElProd_in: type=DT_CoOptmEl_iElProd, value=0
    CoOptmEl_rOfsSoCSTT_in
      value:
        integer literal CoOptmEl_rOfsSoCSTT_in: type=DT_CoOptmEl_rOfsSoCSTT, value=0
    CoOptmEl_rThdRstrtAuthSoCCf1_in
      value:
        integer literal CoOptmEl_rThdRstrtAuthSoCCf1_in: type=DT_CoOptmEl_rThdRstrtAuthSoCCf1, value=0
    CoOptmEl_rThdStopAuthSoCCf2_in
      value:
        integer literal CoOptmEl_rThdStopAuthSoCCf2_in: type=DT_CoOptmEl_rThdStopAuthSoCCf2, value=0
    CoOptmEl_stSoCRefTyp_in
      value:
        integer literal CoOptmEl_stSoCRefTyp_in: type=DT_CoOptmEl_stSoCRefTyp, value=0
    CoPtSynt_stPwt_in
      value:
        integer literal CoPtSynt_stPwt_in: type=DT_CoPtSynt_stPwt, value=1
    CoPtUH_bRStrtReqAvl_in
      value:
        boolean literal CoPtUH_bRStrtReqAvl_in: type=DT_CoPtUH_bRStrtReqAvl, value=false
    CoPtUH_stTypSTTNotAvl_in
      value:
        integer literal CoPtUH_stTypSTTNotAvl_in: type=DT_CoPtUH_stTypSTTNotAvl, value=0
    ECU_bWkuChDchaUcap_in
      value:
        boolean literal ECU_bWkuChDchaUcap_in: type=DT_ECU_bWkuChDchaUcap, value=false
    ECU_bWkuMain_in
      value:
        boolean literal ECU_bWkuMain_in: type=DT_ECU_bWkuMain, value=false
    Ext_bNotAvl_iBattMes_in
      value:
        boolean literal Ext_bNotAvl_iBattMes_in: type=DT_Ext_bNotAvl_iBattMes, value=false
    Ext_bNotAvl_rBattSoC_in
      value:
        boolean literal Ext_bNotAvl_rBattSoC_in: type=DT_Ext_bNotAvl_rBattSoC, value=false
    Ext_bNotAvl_resBattIt_in
      value:
        boolean literal Ext_bNotAvl_resBattIt_in: type=DT_Ext_bNotAvl_resBattIt, value=false
    Ext_bNotAvl_tBattMes_in
      value:
        boolean literal Ext_bNotAvl_tBattMes_in: type=DT_Ext_bNotAvl_tBattMes, value=false
    Ext_bSTTCf_in
      value:
        boolean literal Ext_bSTTCf_in: type=DT_Ext_bSTTCf, value=false
    Ext_bVSSNwAcvSt_in
      value:
        boolean literal Ext_bVSSNwAcvSt_in: type=DT_Ext_bVSSNwAcvSt, value=false
    Ext_rAltCycOp_in
      value:
        integer literal Ext_rAltCycOp_in: type=DT_Ext_rAltCycOp, value=0
    Ext_spdVeh_in
      value:
        integer literal Ext_spdVeh_in: type=DT_Ext_spdVeh, value=0
    Ext_stBattTypCf_in
      value:
        integer literal Ext_stBattTypCf_in: type=DT_Ext_stBattTypCf, value=0
    Ext_stElProdCf_in
      value:
        integer literal Ext_stElProdCf_in: type=DT_Ext_stElProdCf, value=0
    Ext_stTraTypCf_in
      value:
        integer literal Ext_stTraTypCf_in: type=DT_Ext_stTraTypCf, value=0
    Ext_stUcapChSpElMgt_in
      value:
        integer literal Ext_stUcapChSpElMgt_in: type=DT_Ext_stUcapChSpElMgt, value=0
    Ext_stUcapTypCf_in
      value:
        integer literal Ext_stUcapTypCf_in: type=DT_Ext_stUcapTypCf, value=0
    Ext_stVSSCf_in
      value:
        integer literal Ext_stVSSCf_in: type=DT_Ext_stVSSCf, value=0
    RvAltMgt_bAntStopStrtWarn_in
      value:
        boolean literal RvAltMgt_bAntStopStrtWarn_in: type=DT_RvAltMgt_bAntStopStrtWarn, value=false
    RvAltMgt_bStopStrtWarn_in
      value:
        boolean literal RvAltMgt_bStopStrtWarn_in: type=DT_RvAltMgt_bStopStrtWarn, value=false
    RvAltMgt_stRvAltRstrtFbCmd_in
      value:
        integer literal RvAltMgt_stRvAltRstrtFbCmd_in: type=DT_RvAltMgt_stRvAltRstrtFbCmd, value=0
    RvAltMgt_tRvAltStatEstim_in
      value:
        integer literal RvAltMgt_tRvAltStatEstim_in: type=DT_RvAltMgt_tRvAltStatEstim, value=-15
    StaRstrtMgt_bProt10StopInh_in
      value:
        boolean literal StaRstrtMgt_bProt10StopInh_in: type=DT_StaRstrtMgt_bProt10StopInh, value=false
    StaRstrtMgt_stStaRstrtFbCmd_in
      value:
        integer literal StaRstrtMgt_stStaRstrtFbCmd_in: type=DT_StaRstrtMgt_stStaRstrtFbCmd, value=0
    StaStrtMgt_bDmgLimStopInh_in
      value:
        boolean literal StaStrtMgt_bDmgLimStopInh_in: type=DT_StaStrtMgt_bDmgLimStopInh, value=false
    StaStrtMgt_bStaReq_in
      value:
        boolean literal StaStrtMgt_bStaReq_in: type=DT_StaStrtMgt_bStaReq, value=false
    StopStrtEng_stCdnNxtCkg_in
      value:
        integer literal StopStrtEng_stCdnNxtCkg_in: type=DT_StopStrtEng_stCdnNxtCkg, value=0
    VSSCtzMgt_bUcapSerAcvTest_in
      value:
        boolean literal VSSCtzMgt_bUcapSerAcvTest_in: type=DT_VSSCtzMgt_bUcapSerAcvTest, value=true
    VSSCtzMgt_resVSSCtzEstim_in
      value:
        integer literal VSSCtzMgt_resVSSCtzEstim_in: type=DT_VSSCtzMgt_resVSSCtzEstim, value=205
    VSSCtzMgt_rUcapSoHTreat_in
      value:
        integer literal VSSCtzMgt_rUcapSoHTreat_in: type=DT_VSSCtzMgt_rUcapSoHTreat, value=100
    VSSCtzMgt_stUcapDchaRslt_in
      value:
        integer literal VSSCtzMgt_stUcapDchaRslt_in: type=DT_VSSCtzMgt_stUcapDchaRslt, value=0
    VSSCtzMgt_stVSSCtzAcvSt_in
      value:
        integer literal VSSCtzMgt_stVSSCtzAcvSt_in: type=DT_VSSCtzMgt_stVSSCtzAcvSt, value=0
    VSSCtzMgt_stVSSCtzFctLvl_in
      value:
        integer literal VSSCtzMgt_stVSSCtzFctLvl_in: type=DT_VSSCtzMgt_stVSSCtzFctLvl, value=0
    VSSCtzMgt_tUcapMes_in
      value:
        integer literal VSSCtzMgt_tUcapMes_in: type=DT_VSSCtzMgt_tUcapMes, value=40
    VSSCtzMgt_uUcapMes_in
      value:
        integer literal VSSCtzMgt_uUcapMes_in: type=DT_VSSCtzMgt_uUcapMes, value=0
  internal behavior IB_CoEmSTT: component=COEMSTT
    operation invoked event EV_CoEmSTT_AftsNvramRead_1: start-on-event=RE_CoEmSTT_AftsNvramRead_1, operation=P_CoEmSTT_AftsNvramRead_1.op_CoEmSTT_AftsNvramRead_1
    timing event EV_CoEmSTT_002_TEV: mode-dependency=dependent-on-mode=R_UCE_stWkuMainRelSt.RCD_stWkuMainRelSt.Invalid, start-on-event=RE_CoEmSTT_002_TEV, period=0.01
    operation invoked event EV_CoEmSTT_AftsNvramWrite_1: start-on-event=RE_CoEmSTT_AftsNvramWrite_1, operation=P_CoEmSTT_AftsNvramWrite_1.op_CoEmSTT_AftsNvramWrite_1
    operation invoked event EV_CoEmSTT_AftsNvramReset_1: start-on-event=RE_CoEmSTT_AftsNvramReset_1, operation=P_CoEmSTT_AftsNvramReset_1.op_CoEmSTT_AftsNvramReset_1
    mode switch event EV_CoEmSTT_001_MSE: start-on-event=RE_CoEmSTT_001_MSE, activation=ENTRY, mode=R_EcuM_CurrentMode.currentMode.RUN
    5 x runnable:
      RE_CoEmSTT_001_MSE
        31 x data send point:
          ds_CoEmSTT_stTypEmPredRstrt: data-element=P_CoEmSTT_stTypEmPredRstrt.CoEmSTT_stTypEmPredRstrt
          ds_CoEmSTT_rThdStopAuthSoCCf1: data-element=P_CoEmSTT_rThdStopAuthSoCCf1.CoEmSTT_rThdStopAuthSoCCf1
          ds_CoEmSTT_stUcapChSp: data-element=P_CoEmSTT_stUcapChSp.CoEmSTT_stUcapChSp
          ds_CoEmSTT_uUcapSp: data-element=P_CoEmSTT_uUcapSp.CoEmSTT_uUcapSp
          ds_CoEmSTT_bRvAltEngRstrtReq: data-element=P_CoEmSTT_bRvAltEngRstrtReq.CoEmSTT_bRvAltEngRstrtReq
          ds_CoEmSTT_uEmPredRstrt: data-element=P_CoEmSTT_uEmPredRstrt.CoEmSTT_uEmPredRstrt
          ds_CoEmSTT_bVSSCtzStrtAuth: data-element=P_CoEmSTT_bVSSCtzStrtAuth.CoEmSTT_bVSSCtzStrtAuth
          ds_CoEmSTT_bVSSCtzCrit: data-element=P_CoEmSTT_bVSSCtzCrit.CoEmSTT_bVSSCtzCrit
          ds_CoEmSTT_bVSSCtzEngStopAuth: data-element=P_CoEmSTT_bVSSCtzEngStopAuth.CoEmSTT_bVSSCtzEngStopAuth
          ds_CoEmSTT_bUcapUndVolt: data-element=P_CoEmSTT_bUcapUndVolt.CoEmSTT_bUcapUndVolt
          ds_CoEmSTT_bVSSAcvSt: data-element=P_CoEmSTT_bVSSAcvSt.CoEmSTT_bVSSAcvSt
          ds_CoEmSTT_stEngRStrtReq: data-element=P_CoEmSTT_stEngRStrtReq.CoEmSTT_stEngRStrtReq
          ds_CoEmSTT_stEngStopAuth: data-element=P_CoEmSTT_stEngStopAuth.CoEmSTT_stEngStopAuth
          ds_CoEmSTT_ctRstrtAcvTi: data-element=P_CoEmSTT_ctRstrtAcvTi.CoEmSTT_ctRstrtAcvTi
          ds_CoEmSTT_facSen_uEmPredRstrt: data-element=P_CoEmSTT_facSen_uEmPredRstrt.CoEmSTT_facSen_uEmPredRstrt
          ds_CoEmSTT_bBattPrf: data-element=P_CoEmSTT_bBattPrf.CoEmSTT_bBattPrf
          ds_CoEmSTT_iElNwStop: data-element=P_CoEmSTT_iElNwStop.CoEmSTT_iElNwStop
          ds_CoEmSTT_bBattUncrtSoC: data-element=P_CoEmSTT_bBattUncrtSoC.CoEmSTT_bBattUncrtSoC
          ds_CoEmSTT_rThdStopAuthSoCBatt: data-element=P_CoEmSTT_rThdStopAuthSoCBatt.CoEmSTT_rThdStopAuthSoCBatt
          ds_CoEmSTT_bVSSCtzEngRstrtAuth: data-element=P_CoEmSTT_bVSSCtzEngRstrtAuth.CoEmSTT_bVSSCtzEngRstrtAuth
          ds_CoEmSTT_bVSSCtzEngRstrtReq: data-element=P_CoEmSTT_bVSSCtzEngRstrtReq.CoEmSTT_bVSSCtzEngRstrtReq
          ds_CoEmSTT_bRvAltEngStopAuth: data-element=P_CoEmSTT_bRvAltEngStopAuth.CoEmSTT_bRvAltEngStopAuth
          ds_CoEmSTT_stBattEngStopAuth: data-element=P_CoEmSTT_stBattEngStopAuth.CoEmSTT_stBattEngStopAuth
          ds_CoEmSTT_bEngStallAuth: data-element=P_CoEmSTT_bEngStallAuth.CoEmSTT_bEngStallAuth
          ds_CoEmSTT_bBattProt: data-element=P_CoEmSTT_bBattProt.CoEmSTT_bBattProt
          ds_CoEmSTT_bRvAltEngRstrtAuth: data-element=P_CoEmSTT_bRvAltEngRstrtAuth.CoEmSTT_bRvAltEngRstrtAuth
          ds_CoEmSTT_bRvAltCritT: data-element=P_CoEmSTT_bRvAltCritT.CoEmSTT_bRvAltCritT
          ds_CoEmSTT_stBattEngRstrtReq: data-element=P_CoEmSTT_stBattEngRstrtReq.CoEmSTT_stBattEngRstrtReq
          ds_CoEmSTT_bSTTWaitStrtReq: data-element=P_CoEmSTT_bSTTWaitStrtReq.CoEmSTT_bSTTWaitStrtReq
          ds_CoEmSTT_bStaProt: data-element=P_CoEmSTT_bStaProt.CoEmSTT_bStaProt
          ds_CoEmSTT_rThdRstrtAuthSoCBatt: data-element=P_CoEmSTT_rThdRstrtAuthSoCBatt.CoEmSTT_rThdRstrtAuthSoCBatt
      RE_CoEmSTT_AftsNvramWrite_1
      RE_CoEmSTT_002_TEV
        59 x data receive point:
          dr_VSSCtzMgt_uUcapMes: data-element=R_VSSCtzMgt_uUcapMes.VSSCtzMgt_uUcapMes
          dr_Ext_stElProdCf: data-element=R_Ext_stElProdCf.Ext_stElProdCf
          dr_CoOptmEl_stSoCRefTyp: data-element=R_CoOptmEl_stSoCRefTyp.CoOptmEl_stSoCRefTyp
          dr_BatMgt_tBattMes: data-element=R_BatMgt_tBattMes.BatMgt_tBattMes
          dr_BatMgt_stBattSoH: data-element=R_BatMgt_stBattSoH.BatMgt_stBattSoH
          dr_BatMgt_rBattSoCCor: data-element=R_BatMgt_rBattSoCCor.BatMgt_rBattSoCCor
          dr_Ext_tCoMes: data-element=R_Ext_tCoMes.Ext_tCoMes
          dr_Ext_bNotAvl_rBattSoC: data-element=R_Ext_bNotAvl_rBattSoC.Ext_bNotAvl_rBattSoC
          dr_ECU_bWkuMain: data-element=R_ECU_bWkuMain.ECU_bWkuMain
          dr_CoOptmEl_rOfsSoCSTT: data-element=R_CoOptmEl_rOfsSoCSTT.CoOptmEl_rOfsSoCSTT
          dr_CoPtUH_bRStrtReqAvl: data-element=R_CoPtUH_bRStrtReqAvl.CoPtUH_bRStrtReqAvl
          dr_VSSCtzMgt_rUcapSoHTreat: data-element=R_VSSCtzMgt_rUcapSoHTreat.VSSCtzMgt_rUcapSoHTreat
          dr_VSSCtzMgt_stUcapDchaRslt: data-element=R_VSSCtzMgt_stUcapDchaRslt.VSSCtzMgt_stUcapDchaRslt
          dr_RvAltMgt_bStopStrtWarn: data-element=R_RvAltMgt_bStopStrtWarn.RvAltMgt_bStopStrtWarn
          dr_Ext_bNotAvl_tBattMes: data-element=R_Ext_bNotAvl_tBattMes.Ext_bNotAvl_tBattMes
          dr_VSSCtzMgt_tUcapMes: data-element=R_VSSCtzMgt_tUcapMes.VSSCtzMgt_tUcapMes
          dr_Ext_bSTTCf: data-element=R_Ext_bSTTCf.Ext_bSTTCf
          dr_Ext_stUcapTypCf: data-element=R_Ext_stUcapTypCf.Ext_stUcapTypCf
          dr_BatMgt_iBattMes: data-element=R_BatMgt_iBattMes.BatMgt_iBattMes
          dr_StaRstrtMgt_stStaRstrtFbCmd: data-element=R_StaRstrtMgt_stStaRstrtFbCmd.StaRstrtMgt_stStaRstrtFbCmd
          dr_Ext_spdVeh: data-element=R_Ext_spdVeh.Ext_spdVeh
          dr_RvAltMgt_stRvAltRstrtFbCmd: data-element=R_RvAltMgt_stRvAltRstrtFbCmd.RvAltMgt_stRvAltRstrtFbCmd
          dr_CoEmCkg_stRstrtTyp: data-element=R_CoEmCkg_stRstrtTyp.CoEmCkg_stRstrtTyp
          dr_Ext_bNotAvl_resBattIt: data-element=R_Ext_bNotAvl_resBattIt.Ext_bNotAvl_resBattIt
          dr_Ext_bVSSNwAcvSt: data-element=R_Ext_bVSSNwAcvSt.Ext_bVSSNwAcvSt
          dr_RvAltMgt_tRvAltStatEstim: data-element=R_RvAltMgt_tRvAltStatEstim.RvAltMgt_tRvAltStatEstim
          dr_BatMgt_stBattSoC: data-element=R_BatMgt_stBattSoC.BatMgt_stBattSoC
          dr_Ext_stTraTypCf: data-element=R_Ext_stTraTypCf.Ext_stTraTypCf
          dr_StopStrtEng_stCdnNxtCkg: data-element=R_StopStrtEng_stCdnNxtCkg.StopStrtEng_stCdnNxtCkg
          dr_Afts_bVSSCtzActrTestCmd: data-element=R_Afts_bVSSCtzActrTestCmd.Afts_bVSSCtzActrTestCmd
          dr_Afts_bUcapChgIdc: data-element=R_Afts_bUcapChgIdc.Afts_bUcapChgIdc
          dr_VSSCtzMgt_bUcapSerAcvTest: data-element=R_VSSCtzMgt_bUcapSerAcvTest.VSSCtzMgt_bUcapSerAcvTest
          dr_Afts_bLrnRstReq_iElNwStop: data-element=R_Afts_bLrnRstReq_iElNwStop.Afts_bLrnRstReq_iElNwStop
          dr_VSSCtzMgt_stVSSCtzFctLvl: data-element=R_VSSCtzMgt_stVSSCtzFctLvl.VSSCtzMgt_stVSSCtzFctLvl
          dr_CoPtSynt_stPwt: data-element=R_CoPtSynt_stPwt.CoPtSynt_stPwt
          dr_Ext_bNotAvl_iBattMes: data-element=R_Ext_bNotAvl_iBattMes.Ext_bNotAvl_iBattMes
          dr_BatMgt_uBattMinCkg: data-element=R_BatMgt_uBattMinCkg.BatMgt_uBattMinCkg
          dr_CoOptmEl_iElProd: data-element=R_CoOptmEl_iElProd.CoOptmEl_iElProd
          dr_RvAltMgt_bAntStopStrtWarn: data-element=R_RvAltMgt_bAntStopStrtWarn.RvAltMgt_bAntStopStrtWarn
          dr_ECU_bWkuChDchaUcap: data-element=R_ECU_bWkuChDchaUcap.ECU_bWkuChDchaUcap
          dr_CoOptmEl_rThdStopAuthSoCCf2: data-element=R_CoOptmEl_rThdStopAuthSoCCf2.CoOptmEl_rThdStopAuthSoCCf2
          dr_BatMgt_iBattMaxCkg: data-element=R_BatMgt_iBattMaxCkg.BatMgt_iBattMaxCkg
          dr_CoEmCkg_stSTTCf: data-element=R_CoEmCkg_stSTTCf.CoEmCkg_stSTTCf
          dr_Ext_stVSSCf: data-element=R_Ext_stVSSCf.Ext_stVSSCf
          dr_VSSCtzMgt_resVSSCtzEstim: data-element=R_VSSCtzMgt_resVSSCtzEstim.VSSCtzMgt_resVSSCtzEstim
          dr_StaStrtMgt_bStaReq: data-element=R_StaStrtMgt_bStaReq.StaStrtMgt_bStaReq
          dr_Ext_stBattTypCf: data-element=R_Ext_stBattTypCf.Ext_stBattTypCf
          dr_BatMgt_resBattIt: data-element=R_BatMgt_resBattIt.BatMgt_resBattIt
          dr_CoPtUH_bFbSpcFactSTTReq1: data-element=R_CoPtUH_bFbSpcFactSTTReq1.CoPtUH_bFbSpcFactSTTReq1
          dr_BatMgt_uBattMes: data-element=R_BatMgt_uBattMes.BatMgt_uBattMes
          dr_BatMgt_uBattRstrt: data-element=R_BatMgt_uBattRstrt.BatMgt_uBattRstrt
          dr_StaRstrtMgt_bProt10StopInh: data-element=R_StaRstrtMgt_bProt10StopInh.StaRstrtMgt_bProt10StopInh
          dr_CoPtUH_stTypSTTNotAvl: data-element=R_CoPtUH_stTypSTTNotAvl.CoPtUH_stTypSTTNotAvl
          dr_CoOptmEl_rThdRstrtAuthSoCCf1: data-element=R_CoOptmEl_rThdRstrtAuthSoCCf1.CoOptmEl_rThdRstrtAuthSoCCf1
          dr_Ext_stUcapChSpElMgt: data-element=R_Ext_stUcapChSpElMgt.Ext_stUcapChSpElMgt
          dr_Afts_bLrnRstReq_uEmPredRstrt: data-element=R_Afts_bLrnRstReq_uEmPredRstrt.Afts_bLrnRstReq_uEmPredRstrt
          dr_Ext_rAltCycOp: data-element=R_Ext_rAltCycOp.Ext_rAltCycOp
          dr_StaStrtMgt_bDmgLimStopInh: data-element=R_StaStrtMgt_bDmgLimStopInh.StaStrtMgt_bDmgLimStopInh
          dr_VSSCtzMgt_stVSSCtzAcvSt: data-element=R_VSSCtzMgt_stVSSCtzAcvSt.VSSCtzMgt_stVSSCtzAcvSt
        34 x data send point:
          ds_CoEmSTT_bRvAltCritT: data-element=P_CoEmSTT_bRvAltCritT.CoEmSTT_bRvAltCritT
          ds_CoEmSTT_stEngStopAuth: data-element=P_CoEmSTT_stEngStopAuth.CoEmSTT_stEngStopAuth
          ds_CoEmSTT_bVSSCtzEngStopAuth: data-element=P_CoEmSTT_bVSSCtzEngStopAuth.CoEmSTT_bVSSCtzEngStopAuth
          ds_CoEmSTT_bVSSCtzCrit: data-element=P_CoEmSTT_bVSSCtzCrit.CoEmSTT_bVSSCtzCrit
          ds_CoEmSTT_bBattProt: data-element=P_CoEmSTT_bBattProt.CoEmSTT_bBattProt
          ds_CoEmSTT_bBattPrf: data-element=P_CoEmSTT_bBattPrf.CoEmSTT_bBattPrf
          ds_CoEmSTT_bUcapDchaAuth: data-element=P_CoEmSTT_bUcapDchaAuth.CoEmSTT_bUcapDchaAuth
          ds_CoEmSTT_tiVSSTmrStrtAuth: data-element=P_CoEmSTT_tiVSSTmrStrtAuth.CoEmSTT_tiVSSTmrStrtAuth
          ds_CoEmSTT_facSen_uEmPredRstrt: data-element=P_CoEmSTT_facSen_uEmPredRstrt.CoEmSTT_facSen_uEmPredRstrt
          ds_CoEmSTT_stBattEngStopAuth: data-element=P_CoEmSTT_stBattEngStopAuth.CoEmSTT_stBattEngStopAuth
          ds_CoEmSTT_bVSSCtzStrtAuth: data-element=P_CoEmSTT_bVSSCtzStrtAuth.CoEmSTT_bVSSCtzStrtAuth
          ds_CoEmSTT_stUcapChSp: data-element=P_CoEmSTT_stUcapChSp.CoEmSTT_stUcapChSp
          ds_CoEmSTT_bSTTWaitStrtReq: data-element=P_CoEmSTT_bSTTWaitStrtReq.CoEmSTT_bSTTWaitStrtReq
          ds_CoEmSTT_bRvAltEngRstrtAuth: data-element=P_CoEmSTT_bRvAltEngRstrtAuth.CoEmSTT_bRvAltEngRstrtAuth
          ds_CoEmSTT_bRvAltEngStopAuth: data-element=P_CoEmSTT_bRvAltEngStopAuth.CoEmSTT_bRvAltEngStopAuth
          ds_CoEmSTT_iElNwStop: data-element=P_CoEmSTT_iElNwStop.CoEmSTT_iElNwStop
          ds_CoEmSTT_uUcapSp: data-element=P_CoEmSTT_uUcapSp.CoEmSTT_uUcapSp
          ds_CoEmSTT_bOverThdUcapBoost: data-element=P_CoEmSTT_bOverThdUcapBoost.CoEmSTT_bOverThdUcapBoost
          ds_CoEmSTT_bVSSCtzEngRstrtAuth: data-element=P_CoEmSTT_bVSSCtzEngRstrtAuth.CoEmSTT_bVSSCtzEngRstrtAuth
          ds_CoEmSTT_uEmPredRstrt: data-element=P_CoEmSTT_uEmPredRstrt.CoEmSTT_uEmPredRstrt
          ds_CoEmSTT_stTypEmPredRstrt: data-element=P_CoEmSTT_stTypEmPredRstrt.CoEmSTT_stTypEmPredRstrt
          ds_CoEmSTT_rThdStopAuthSoCBatt: data-element=P_CoEmSTT_rThdStopAuthSoCBatt.CoEmSTT_rThdStopAuthSoCBatt
          ds_CoEmSTT_rThdRstrtAuthSoCBatt: data-element=P_CoEmSTT_rThdRstrtAuthSoCBatt.CoEmSTT_rThdRstrtAuthSoCBatt
          ds_CoEmSTT_bVSSCtzEngRstrtReq: data-element=P_CoEmSTT_bVSSCtzEngRstrtReq.CoEmSTT_bVSSCtzEngRstrtReq
          ds_CoEmSTT_bBattUncrtSoC: data-element=P_CoEmSTT_bBattUncrtSoC.CoEmSTT_bBattUncrtSoC
          ds_CoEmSTT_rThdStopAuthSoCCf1: data-element=P_CoEmSTT_rThdStopAuthSoCCf1.CoEmSTT_rThdStopAuthSoCCf1
          ds_CoEmSTT_bEngStallAuth: data-element=P_CoEmSTT_bEngStallAuth.CoEmSTT_bEngStallAuth
          ds_CoEmSTT_ctRstrtAcvTi: data-element=P_CoEmSTT_ctRstrtAcvTi.CoEmSTT_ctRstrtAcvTi
          ds_CoEmSTT_stBattEngRstrtReq: data-element=P_CoEmSTT_stBattEngRstrtReq.CoEmSTT_stBattEngRstrtReq
          ds_CoEmSTT_bRvAltEngRstrtReq: data-element=P_CoEmSTT_bRvAltEngRstrtReq.CoEmSTT_bRvAltEngRstrtReq
          ds_CoEmSTT_stEngRStrtReq: data-element=P_CoEmSTT_stEngRStrtReq.CoEmSTT_stEngRStrtReq
          ds_CoEmSTT_bUcapUndVolt: data-element=P_CoEmSTT_bUcapUndVolt.CoEmSTT_bUcapUndVolt
          ds_CoEmSTT_bStaProt: data-element=P_CoEmSTT_bStaProt.CoEmSTT_bStaProt
          ds_CoEmSTT_bVSSAcvSt: data-element=P_CoEmSTT_bVSSAcvSt.CoEmSTT_bVSSAcvSt
        12 x sync call:
          ssp_FRM_bInhCoEmSTTNwCurClcStop: operation=R_FRM_bInhCoEmSTTNwCurClcStop.GetFunctionPermission
          ssp_FRM_bInhCoEmSTT_uVSSCtzRstrt: operation=R_FRM_bInhCoEmSTT_uVSSCtzRstrt.GetFunctionPermission
          ssp_FRM_bAcvCoEmSTTCutReq: operation=R_FRM_bAcvCoEmSTTCutReq.GetFunctionPermission
          ssp_FRM_bAcvCoEmSTTRstrtReq: operation=R_FRM_bAcvCoEmSTTRstrtReq.GetFunctionPermission
          ssp_FRM_bAcvCoEmSTTVSSCtzStrt: operation=R_FRM_bAcvCoEmSTTVSSCtzStrt.GetFunctionPermission
          ssp_FRM_bInhCoEmSTTWaitStrt: operation=R_FRM_bInhCoEmSTTWaitStrt.GetFunctionPermission
          ssp_FRM_bInhCoEmSTT_uEmPredRstrt: operation=R_FRM_bInhCoEmSTT_uEmPredRstrt.GetFunctionPermission
          ssp_FRM_bInhCoEmSTTStopAuth: operation=R_FRM_bInhCoEmSTTStopAuth.GetFunctionPermission
          ssp_FRM_bInhCoEmSTTVSSCtzStrt: operation=R_FRM_bInhCoEmSTTVSSCtzStrt.GetFunctionPermission
          ssp_FRM_bAcvCoEmSTTDftUcapVoltSp: operation=R_FRM_bAcvCoEmSTTDftUcapVoltSp.GetFunctionPermission
          ssp_FRM_bInhCoEmSTTNwCurMv: operation=R_FRM_bInhCoEmSTTNwCurMv.GetFunctionPermission
          ssp_FRM_bAcvCoEmSTTDftUcapCurSp: operation=R_FRM_bAcvCoEmSTTDftUcapCurSp.GetFunctionPermission
      RE_CoEmSTT_AftsNvramRead_1
      RE_CoEmSTT_AftsNvramReset_1
  swc implementation Imp_CoEmSTT: programming-language=C, behavior=IB_CoEmSTT
    code-descriptors:
      code CodeDescriptor: type=SRC
        10 x xfile:
          CoEmSTT_MemMap_h: url=CoEmSTT_MemMap.h
          CoEmSTT_nvm_h: url=CoEmSTT_nvm.h
          CoEmSTT_002_TEV_fct_c: url=CoEmSTT_002_TEV_fct.c
          CoEmSTT_002_calibrations_c: url=CoEmSTT_002_calibrations.c
          CoEmSTT_h: url=CoEmSTT.h
          CoEmSTT_nvm_c: url=CoEmSTT_nvm.c
          CoEmSTT_002_TEV_fct_h: url=CoEmSTT_002_TEV_fct.h
          CoEmSTT_afts_c: url=CoEmSTT_afts.c
          CoEmSTT_002_calibrations_h: url=CoEmSTT_002_calibrations.h
          CoEmSTT_c: url=CoEmSTT.c
